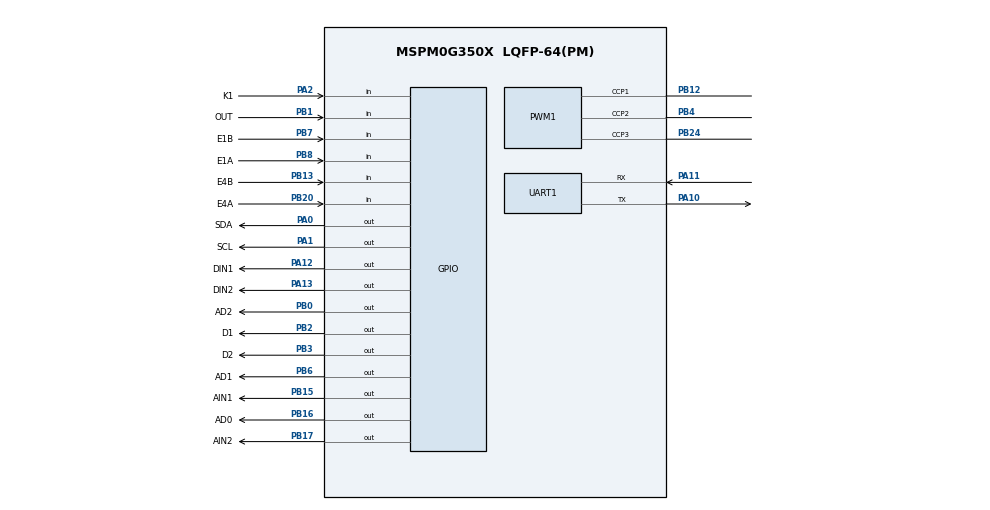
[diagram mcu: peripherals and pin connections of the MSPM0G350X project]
/**
 * @cliArgs --device "MSPM0G350X" --part "Default" --package "LQFP-64(PM)" --product "mspm0_sdk@2.11.00.07"
 * @versions {"tool":"1.28.0"}
 */

/**
 * Import the modules used in this configuration.
 */
const GPIO    = scripting.addModule("/ti/driverlib/GPIO", {}, false);
const GPIO1   = GPIO.addInstance();
const GPIO2   = GPIO.addInstance();
const GPIO3   = GPIO.addInstance();
const GPIO4   = GPIO.addInstance();
const GPIO5   = GPIO.addInstance();
const GPIO6   = GPIO.addInstance();
const PWM     = scripting.addModule("/ti/driverlib/PWM", {}, false);
const PWM1    = PWM.addInstance();
const SYSCTL  = scripting.addModule("/ti/driverlib/SYSCTL");
const SYSTICK = scripting.addModule("/ti/driverlib/SYSTICK");
const TIMER   = scripting.addModule("/ti/driverlib/TIMER", {}, false);
const TIMER1  = TIMER.addInstance();
const UART    = scripting.addModule("/ti/driverlib/UART", {}, false);
const UART1   = UART.addInstance();

/**
 * Write custom configuration values to the imported modules.
 */
const divider9       = system.clockTree["UDIV"];
divider9.divideValue = 2;

const gate7  = system.clockTree["MFCLKGATE"];
gate7.enable = true;

const multiplier2         = system.clockTree["PLL_QDIV"];
multiplier2.multiplyValue = 5;

const mux8       = system.clockTree["HSCLKMUX"];
mux8.inputSelect = "HSCLKMUX_SYSPLL0";

GPIO1.$name                         = "LED";
GPIO1.port                          = "PORTB";
GPIO1.associatedPins.create(2);
GPIO1.associatedPins[0].$name       = "D1";
GPIO1.associatedPins[0].pin.$assign = "PB2";
GPIO1.associatedPins[1].$name       = "D2";
GPIO1.associatedPins[1].pin.$assign = "PB3";

const Board = scripting.addModule("/ti/driverlib/Board", {}, false);

GPIO2.$name                         = "KEY";
GPIO2.associatedPins[0].direction   = "INPUT";
GPIO2.associatedPins[0].$name       = "K1";
GPIO2.associatedPins[0].pin.$assign = "PA2";

GPIO3.$name                          = "MPU6050";
GPIO3.associatedPins.create(2);
GPIO3.associatedPins[0].$name        = "SCL";
GPIO3.associatedPins[0].initialValue = "SET";
GPIO3.associatedPins[0].ioStructure  = "OD";
GPIO3.associatedPins[0].pin.$assign  = "PA1";
GPIO3.associatedPins[1].$name        = "SDA";
GPIO3.associatedPins[1].initialValue = "SET";
GPIO3.associatedPins[1].ioStructure  = "OD";
GPIO3.associatedPins[1].pin.$assign  = "PA0";

GPIO4.$name                           = "MOTOR_DIR";
GPIO4.associatedPins.create(4);
GPIO4.associatedPins[0].$name         = "AIN1";
GPIO4.associatedPins[0].pin.$assign   = "PB15";
GPIO4.associatedPins[1].$name         = "AIN2";
GPIO4.associatedPins[1].pin.$assign   = "PB17";
GPIO4.associatedPins[2].$name         = "DIN1";
GPIO4.associatedPins[2].pin.$assign   = "PA12";
GPIO4.associatedPins[3].$name         = "DIN2";
GPIO4.associatedPins[3].pin.$assign   = "PA13";

GPIO5.$name                           = "ENCODER";
GPIO5.port                            = "PORTB";
GPIO5.associatedPins.create(4);
GPIO5.associatedPins[0].$name         = "E1A";
GPIO5.associatedPins[0].direction     = "INPUT";
GPIO5.associatedPins[0].interruptEn   = true;
GPIO5.associatedPins[0].polarity      = "RISE_FALL";
GPIO5.associatedPins[0].pin.$assign   = "PB8";
GPIO5.associatedPins[1].$name         = "E1B";
GPIO5.associatedPins[1].direction     = "INPUT";
GPIO5.associatedPins[1].interruptEn   = true;
GPIO5.associatedPins[1].polarity      = "RISE_FALL";
GPIO5.associatedPins[1].pin.$assign   = "PB7";
GPIO5.associatedPins[2].$name         = "E4A";
GPIO5.associatedPins[2].direction     = "INPUT";
GPIO5.associatedPins[2].interruptEn   = true;
GPIO5.associatedPins[2].polarity      = "RISE_FALL";
GPIO5.associatedPins[2].pin.$assign   = "PB20";
GPIO5.associatedPins[3].$name         = "E4B";
GPIO5.associatedPins[3].direction     = "INPUT";
GPIO5.associatedPins[3].interruptEn   = true;
GPIO5.associatedPins[3].polarity      = "RISE_FALL";
GPIO5.associatedPins[3].pin.$assign   = "PB13";

GPIO6.$name                           = "GRAYSCALE";
GPIO6.port                            = "PORTB";
GPIO6.associatedPins.create(4);
GPIO6.associatedPins[0].$name         = "AD2";
GPIO6.associatedPins[0].pin.$assign   = "PB0";
GPIO6.associatedPins[1].$name         = "AD1";
GPIO6.associatedPins[1].pin.$assign   = "PB6";
GPIO6.associatedPins[2].$name         = "AD0";
GPIO6.associatedPins[2].pin.$assign   = "PB16";
GPIO6.associatedPins[3].$name         = "OUT";
GPIO6.associatedPins[3].direction     = "INPUT";
GPIO6.associatedPins[3].pin.$assign   = "PB1";

PWM1.$name                      = "BUZZER";
PWM1.pwmMode                    = "EDGE_ALIGN_UP";
PWM1.ccIndex                    = [1,2,3];
PWM1.clockDivider               = 2;
PWM1.clockPrescale              = 16;
PWM1.peripheral.ccp1Pin.$assign = "PB12";
PWM1.peripheral.ccp2Pin.$assign = "PB4";
PWM1.peripheral.ccp3Pin.$assign = "PB24";
PWM1.PWM_CHANNEL_1.$name        = "ti_driverlib_pwm_PWMTimerCC1";
PWM1.PWM_CHANNEL_1.dutyCycle    = 0;
PWM1.PWM_CHANNEL_2.$name        = "ti_driverlib_pwm_PWMTimerCC2";
PWM1.PWM_CHANNEL_2.dutyCycle    = 0;
PWM1.PWM_CHANNEL_3.$name        = "ti_driverlib_pwm_PWMTimerCC0";
PWM1.PWM_CHANNEL_3.dutyCycle    = 0;
PWM1.ccp1PinConfig.$name        = "ti_driverlib_gpio_GPIOPinGeneric4";
PWM1.ccp2PinConfig.$name        = "ti_driverlib_gpio_GPIOPinGeneric5";
PWM1.ccp3PinConfig.$name        = "ti_driverlib_gpio_GPIOPinGeneric6";

SYSCTL.forceDefaultClkConfig = true;
SYSCTL.clockTreeEn           = true;

SYSTICK.periodEnable  = true;
SYSTICK.systickEnable = true;
SYSTICK.period        = 80;

TIMER1.$name              = "TIMER_0";
TIMER1.timerPeriod        = "1 ms";
TIMER1.timerClkDiv        = 8;
TIMER1.timerMode          = "PERIODIC";
TIMER1.interrupts         = ["ZERO"];
TIMER1.interruptPriority  = "0";
TIMER1.peripheral.$assign = "TIMG0";

UART1.$name                    = "UART_0";
UART1.uartClkSrc               = "MFCLK";
UART1.enabledInterrupts        = ["RX"];
UART1.targetBaudRate           = 115200;
UART1.interruptPriority        = "3";
UART1.peripheral.rxPin.$assign = "PA11";
UART1.peripheral.txPin.$assign = "PA10";
UART1.txPinConfig.$name        = "ti_driverlib_gpio_GPIOPinGeneric0";
UART1.rxPinConfig.$name        = "ti_driverlib_gpio_GPIOPinGeneric1";

/**
 * Pinmux solution for unlocked pins/peripherals. This ensures that minor changes to the automatic solver in a future
 * version of the tool will not impact the pinmux you originally saw.  These lines can be completely deleted in order to
 * re-solve from scratch.
 */
Board.peripheral.$suggestSolution          = "DEBUGSS";
Board.peripheral.swclkPin.$suggestSolution = "PA20";
Board.peripheral.swdioPin.$suggestSolution = "PA19";
PWM1.peripheral.$suggestSolution           = "TIMA0";
UART1.peripheral.$suggestSolution          = "UART0";
